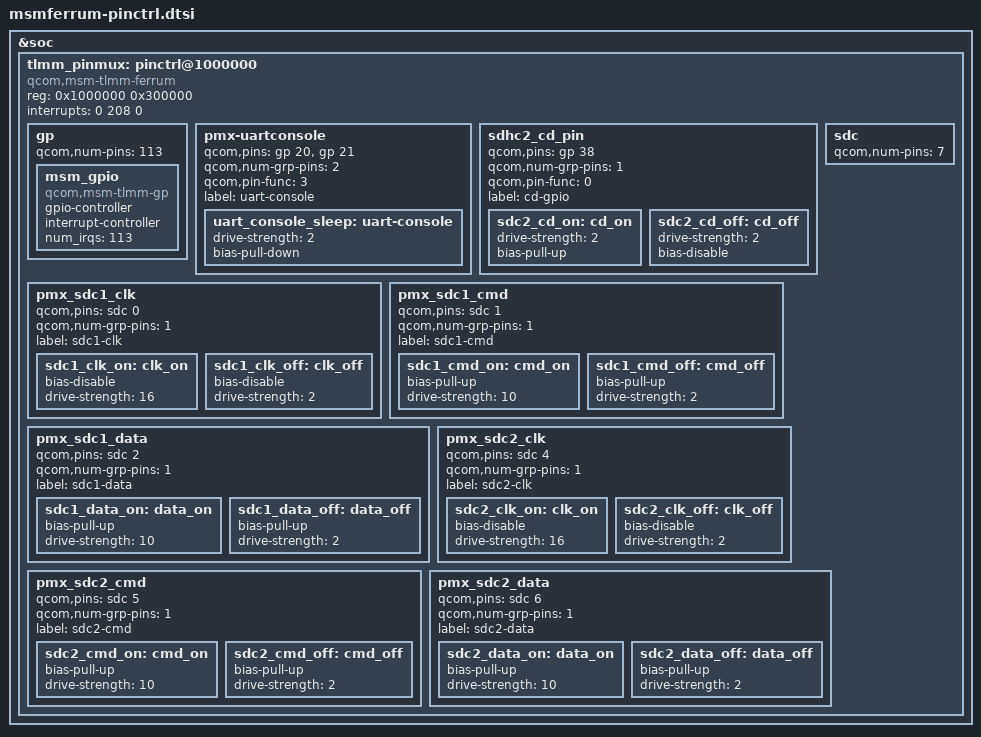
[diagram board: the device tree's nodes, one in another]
/* Copyright (c) 2014, The Linux Foundation. All rights reserved.
 *
 * This program is free software; you can redistribute it and/or modify
 * it under the terms of the GNU General Public License version 2 and
 * only version 2 as published by the Free Software Foundation.
 *
 * This program is distributed in the hope that it will be useful,
 * but WITHOUT ANY WARRANTY; without even the implied warranty of
 * MERCHANTABILITY or FITNESS FOR A PARTICULAR PURPOSE.  See the
 * GNU General Public License for more details.
 */

&soc {
	tlmm_pinmux: pinctrl@1000000 {
		compatible = "qcom,msm-tlmm-ferrum", "qcom,msm-tlmm-8916";
		reg = <0x1000000 0x300000>;
		interrupts = <0 208 0>;

		/*General purpose pins*/
		gp: gp {
			qcom,num-pins = <113>;
			#qcom,pin-cells = <1>;
			msm_gpio: msm_gpio {
				compatible = "qcom,msm-tlmm-gp";
				gpio-controller;
				#gpio-cells = <2>;
				interrupt-controller;
				#interrupt-cells = <2>;
				num_irqs = <113>;
			};
		};

		pmx-uartconsole {
			qcom,pins = <&gp 20>, <&gp 21>;
			qcom,num-grp-pins = <2>;
			qcom,pin-func = <3>;
			label = "uart-console";
			uart_console_sleep: uart-console {
				drive-strength = <2>;
				bias-pull-down;
			};
		};

		sdhc2_cd_pin {
			qcom,pins = <&gp 38>;
			qcom,num-grp-pins = <1>;
			qcom,pin-func = <0>;
			label = "cd-gpio";
			sdc2_cd_on: cd_on {
				drive-strength = <2>;
				bias-pull-up;
			};
			sdc2_cd_off: cd_off {
				drive-strength = <2>;
				bias-disable;
			};
		};

		/* SDC pin type */
		sdc: sdc {
			/* 0-2 for sdc1 4-6 for sdc2 */
			qcom,num-pins = <7>;
			/* Order of pins */
			/* SDC1: CLK -> 0, CMD -> 1, DATA -> 2 */
			/* SDC2: CLK -> 4, CMD -> 5, DATA -> 6 */
			#qcom,pin-cells = <1>;
		};

		pmx_sdc1_clk {
			qcom,pins = <&sdc 0>;
			qcom,num-grp-pins = <1>;
			label = "sdc1-clk";
			sdc1_clk_on: clk_on {
				bias-disable; /* NO pull */
				drive-strength = <16>; /* 16 MA */
			};
			sdc1_clk_off: clk_off {
				bias-disable; /* NO pull */
				drive-strength = <2>; /* 2 MA */
			};
		};

		pmx_sdc1_cmd {
			qcom,pins = <&sdc 1>;
			qcom,num-grp-pins = <1>;
			label = "sdc1-cmd";
			sdc1_cmd_on: cmd_on {
				bias-pull-up; /* pull up */
				drive-strength = <10>; /* 10 MA */
			};
			sdc1_cmd_off: cmd_off {
				bias-pull-up; /* pull up */
				drive-strength = <2>; /* 2 MA */
			};
		};

		pmx_sdc1_data {
			qcom,pins = <&sdc 2>;
			qcom,num-grp-pins = <1>;
			label = "sdc1-data";
			sdc1_data_on: data_on {
				bias-pull-up; /* pull up */
				drive-strength = <10>; /* 10 MA */
			};
			sdc1_data_off: data_off {
				bias-pull-up; /* pull up */
				drive-strength = <2>; /* 2 MA */
			};
		};

		pmx_sdc2_clk {
			qcom,pins = <&sdc 4>;
			qcom,num-grp-pins = <1>;
			label = "sdc2-clk";
			sdc2_clk_on: clk_on {
				bias-disable; /* NO pull */
				drive-strength = <16>; /* 16 MA */
			};
			sdc2_clk_off: clk_off {
				bias-disable; /* NO pull */
				drive-strength = <2>; /* 2 MA */
			};
		};

		pmx_sdc2_cmd {
			qcom,pins = <&sdc 5>;
			qcom,num-grp-pins = <1>;
			label = "sdc2-cmd";
			sdc2_cmd_on: cmd_on {
				bias-pull-up; /* pull up */
				drive-strength = <10>; /* 10 MA */
			};
			sdc2_cmd_off: cmd_off {
				bias-pull-up; /* pull up */
				drive-strength = <2>; /* 2 MA */
			};
		};

		pmx_sdc2_data {
			qcom,pins = <&sdc 6>;
			qcom,num-grp-pins = <1>;
			label = "sdc2-data";
			sdc2_data_on: data_on {
				bias-pull-up; /* pull up */
				drive-strength = <10>; /* 10 MA */
			};
			sdc2_data_off: data_off {
				bias-pull-up; /* pull up */
				drive-strength = <2>; /* 2 MA */
			};
		};
	};
};
